# ESP32-P4 register map
Vendor: ESPRESSIF SYSTEMS (SHANGHAI) CO., LTD.; Series: ESP32 P-Series; File version: 3
CPU: RV32IMAFC r0p0, little endian, no MPU, FPU, 0 interrupt priority bits
Address unit: 32 bits
Registers are 32-bit, read-write, reset 0x0 unless marked. A register's access mark holds for its fields unless they carry their own. Offsets are from the block's base; [hi:lo] are bit positions; lines under a group give offsets from that group; {n}, {i} and the like mark numbered series; 'fields as' and 'values as' point back to an identical list.

## H264_DMA — H264 Encoder (DMA)
Base 0x500A7000
{0x0+0x100*i} OUT_CH{i} (i=0..4) group — Cluster OUT_CH{i}, containing OUT_CONF0_CH?, OUT_INT_RAW_CH?, OUT_INT_ENA_CH?, OUT_INT_ST_CH?, OUT_INT_CLR_CH?, OUTFIFO_STATUS_CH?, OUT_PUSH_CH?, OUT_LINK_CONF_CH?, OUT_LINK_ADDR_CH?, OUT_STATE_CH?, OUT_EOF_DES_ADDR_CH?, OUT_DSCR_CH?, OUT_DSCR_BF0_CH?, OUT_DSCR_BF1_CH?, OUT_ARB_CH?, OUT_RO_STATUS_CH?, OUT_RO_PD_CONF_CH?, OUT_MODE_ENABLE_CH?, OUT_MODE_YUV_CH?, OUT_ETM_CONF_CH?, OUT_BUF_LEN_CH?, OUT_FIFO_BCNT_CH?, OUT_PUSH_BYTECNT_CH?, OUT_XADDR_CH?, OUT_BLOCK_BUF_LEN_CH?
  0x00 CONF0 reset 0x2 — TX CHx config0 register
    [26] OUT_ARB_WEIGHT_OPT_DIS — Set this bit to 1 to disable arbiter optimum weight function.
    [25] OUT_CMD_DISABLE — Write 1 before reset and write 0 after reset
    [24] OUT_RST — Write 1 then write 0 to this bit to reset TX channel
    [16] OUT_REORDER_EN — Enable TX channel 0 macro block reorder when set to 1, only channel0 have this selection
    [12] OUT_PAGE_BOUND_EN — Set this bit to 1 to make sure AXI read data don't cross the address boundary which define by mem_burst_length
    [8:6] OUT_MEM_BURST_LENGTH — Block size of Tx channel 0. 0: single 1: 16 bytes 2: 32 bytes 3: 64 bytes 4: 128 bytes
    [4] OUT_CHECK_OWNER — Set this bit to enable checking the owner attribute of the link descriptor.
    [3] OUT_ECC_AES_EN — When access address space is ecc/aes area, this bit should be set to 1. In this case, the start address of square should be 16-bit aligned. The width of square multiply byte number of one pixel should be 16-bit aligned.
    [2] OUTDSCR_BURST_EN — Set this bit to 1 to enable INCR burst transfer for Tx channel 0 reading link descriptor when accessing internal SRAM.
    [1] OUT_EOF_MODE — EOF flag generation mode when receiving data. 1: EOF flag for Tx channel 0 is generated when data need to read has been popped from FIFO in DMA
    [0] OUT_AUTO_WRBACK — Set this bit to enable automatic outlink-writeback when all the data pointed by outlink descriptor has been received.
  0x04 INT_RAW — TX CHx interrupt raw register
    [8] OUT_DSCR_TASK_OVF — The raw interrupt bit turns to high level when dscr ready task fifo is overflow.
    [7] OUTFIFO_UDF_L2 — The raw interrupt bit turns to high level when fifo is underflow.
    [6] OUTFIFO_OVF_L2 — The raw interrupt bit turns to high level when fifo is overflow.
    [5] OUTFIFO_UDF_L1 — The raw interrupt bit turns to high level when fifo is underflow.
    [4] OUTFIFO_OVF_L1 — The raw interrupt bit turns to high level when fifo is overflow.
    [3] OUT_TOTAL_EOF — The raw interrupt bit turns to high level when data corresponding a outlink (includes one link descriptor or few link descriptors) is transmitted out for Tx channel 0.
    [2] OUT_DSCR_ERR — The raw interrupt bit turns to high level when detecting outlink descriptor error, including owner error, the second and third word error of outlink descriptor for Tx channel 0.
    [1] OUT_EOF — The raw interrupt bit turns to high level when the last data pointed by one outlink descriptor has been read from memory for Tx channel 0.
    [0] OUT_DONE — The raw interrupt bit turns to high level when the last data pointed by one outlink descriptor has been transmitted to peripherals for Tx channel 0.
  0x08 INT_ENA — TX CHx interrupt ena register
    [8] OUT_DSCR_TASK_OVF — The interrupt enable bit for the OUT_DSCR_TASK_OVF_CH_INT interrupt.
    [7] OUTFIFO_UDF_L2 — The interrupt enable bit for the OUTFIFO_UDF_L2_CH_INT interrupt.
    [6] OUTFIFO_OVF_L2 — The interrupt enable bit for the OUTFIFO_OVF_L2_CH_INT interrupt.
    [5] OUTFIFO_UDF_L1 — The interrupt enable bit for the OUTFIFO_UDF_L1_CH_INT interrupt.
    [4] OUTFIFO_OVF_L1 — The interrupt enable bit for the OUTFIFO_OVF_L1_CH_INT interrupt.
    [3] OUT_TOTAL_EOF — The interrupt enable bit for the OUT_TOTAL_EOF_CH_INT interrupt.
    [2] OUT_DSCR_ERR — The interrupt enable bit for the OUT_DSCR_ERR_CH_INT interrupt.
    [1] OUT_EOF — The interrupt enable bit for the OUT_EOF_CH_INT interrupt.
    [0] OUT_DONE — The interrupt enable bit for the OUT_DONE_CH_INT interrupt.
  0x0C INT_ST ro — TX CHx interrupt st register
    [8] OUT_DSCR_TASK_OVF — The raw interrupt status bit for the OUT_DSCR_TASK_OVF_CH_INT interrupt.
    [7] OUTFIFO_UDF_L2 — The raw interrupt status bit for the OUTFIFO_UDF_L2_CH_INT interrupt.
    [6] OUTFIFO_OVF_L2 — The raw interrupt status bit for the OUTFIFO_OVF_L2_CH_INT interrupt.
    [5] OUTFIFO_UDF_L1 — The raw interrupt status bit for the OUTFIFO_UDF_L1_CH_INT interrupt.
    [4] OUTFIFO_OVF_L1 — The raw interrupt status bit for the OUTFIFO_OVF_L1_CH_INT interrupt.
    [3] OUT_TOTAL_EOF — The raw interrupt status bit for the OUT_TOTAL_EOF_CH_INT interrupt.
    [2] OUT_DSCR_ERR — The raw interrupt status bit for the OUT_DSCR_ERR_CH_INT interrupt.
    [1] OUT_EOF — The raw interrupt status bit for the OUT_EOF_CH_INT interrupt.
    [0] OUT_DONE — The raw interrupt status bit for the OUT_DONE_CH_INT interrupt.
  0x10 INT_CLR wo — TX CHx interrupt clr register
    [8] OUT_DSCR_TASK_OVF write-1-clears — Set this bit to clear the OUT_DSCR_TASK_OVF_CH_INT interrupt.
    [7] OUTFIFO_UDF_L2 write-1-clears — Set this bit to clear the OUTFIFO_UDF_L2_CH_INT interrupt.
    [6] OUTFIFO_OVF_L2 write-1-clears — Set this bit to clear the OUTFIFO_OVF_L2_CH_INT interrupt.
    [5] OUTFIFO_UDF_L1 write-1-clears — Set this bit to clear the OUTFIFO_UDF_L1_CH_INT interrupt.
    [4] OUTFIFO_OVF_L1 write-1-clears — Set this bit to clear the OUTFIFO_OVF_L1_CH_INT interrupt.
    [3] OUT_TOTAL_EOF write-1-clears — Set this bit to clear the OUT_TOTAL_EOF_CH_INT interrupt.
    [2] OUT_DSCR_ERR write-1-clears — Set this bit to clear the OUT_DSCR_ERR_CH_INT interrupt.
    [1] OUT_EOF write-1-clears — Set this bit to clear the OUT_EOF_CH_INT interrupt.
    [0] OUT_DONE write-1-clears — Set this bit to clear the OUT_DONE_CH_INT interrupt.
  0x14 FIFO_STATUS ro reset 0x20082 — TX CHx outfifo status register
    [19:18] OUTFIFO_CNT_L3 — The register stores the 8byte number of the data in Tx FIFO for Tx channel 0.
    [17] OUTFIFO_EMPTY_L3 — Tx FIFO empty signal for Tx channel 0.
    [16] OUTFIFO_FULL_L3 — Tx FIFO full signal for Tx channel 0.
    [12:8] OUTFIFO_CNT_L1 — The register stores the byte number of the data in Tx FIFO for Tx channel 0.
    [7] OUTFIFO_EMPTY_L1 — Tx FIFO empty signal for Tx channel 0.
    [6] OUTFIFO_FULL_L1 — Tx FIFO full signal for Tx channel 0.
    [5:2] OUTFIFO_CNT_L2 — The register stores the byte number of the data in Tx FIFO for Tx channel 0.
    [1] OUTFIFO_EMPTY_L2 — Tx FIFO empty signal for Tx channel 0.
    [0] OUTFIFO_FULL_L2 — Tx FIFO full signal for Tx channel 0.
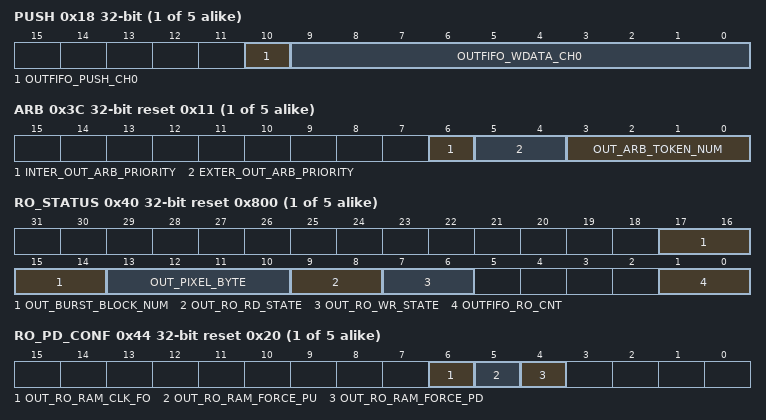
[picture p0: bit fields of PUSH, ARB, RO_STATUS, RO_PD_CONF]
  0x18 PUSH — TX CHx outfifo push register
    [10] OUTFIFO_PUSH_CH0 — Set this bit to push data into DMA Tx FIFO.
    [9:0] OUTFIFO_WDATA_CH0 — This register stores the data that need to be pushed into DMA Tx FIFO.
  0x1C LINK_CONF access per field reset 0x800000 — TX CHx out_link dscr ctrl register
    [23] OUTLINK_PARK ro — 1: the outlink descriptor's FSM is in idle state. 0: the outlink descriptor's FSM is working.
    [22] OUTLINK_RESTART rw — Set this bit to restart a new outlink from the last address.
    [21] OUTLINK_START rw — Set this bit to start dealing with the outlink descriptors.
    [20] OUTLINK_STOP rw — Set this bit to stop dealing with the outlink descriptors.
  0x20 LINK_ADDR — TX CHx out_link dscr addr register
    [31:0] OUTLINK_ADDR — This register stores the first outlink descriptor's address.
  0x24 STATE ro reset 0x1000000 — TX CHx state register
    [24] OUT_RESET_AVAIL — This register indicate that if the channel reset is safety.
    [23:20] OUT_STATE — This register stores the current control module state machine state.
    [19:18] OUT_DSCR_STATE — This register stores the current descriptor state machine state.
    [17:0] OUTLINK_DSCR_ADDR — This register stores the current outlink descriptor's address.
  0x28 EOF_DES_ADDR ro — TX CHx eof des addr register
    [31:0] OUT_EOF_DES_ADDR — This register stores the address of the outlink descriptor when the EOF bit in this descriptor is 1.
  0x2C DSCR ro — TX CHx next dscr addr register
    [31:0] OUTLINK_DSCR — The address of the next outlink descriptor address y.
  0x30 DSCR_BF0 ro — TX CHx last dscr addr register
    [31:0] OUTLINK_DSCR_BF0 — The address of the last outlink descriptor's next address y-1.
  0x34 DSCR_BF1 ro — TX CHx second-to-last dscr addr register
    [31:0] OUTLINK_DSCR_BF1 — The address of the second-to-last outlink descriptor's next address y-2.
  0x3C ARB reset 0x11 — TX CHx arb register
    [6] INTER_OUT_ARB_PRIORITY — Set the priority of channel
    [5:4] EXTER_OUT_ARB_PRIORITY — Set the priority of channel
    [3:0] OUT_ARB_TOKEN_NUM — Set the max number of token count of arbiter
  0x40 RO_STATUS ro reset 0x800 — TX CHx reorder status register. Available on CH0
    [17:14] OUT_BURST_BLOCK_NUM — the number of macro blocks contained in a burst of data at TX channel
    [13:10] OUT_PIXEL_BYTE — the number of bytes contained in a pixel at TX channel 0: 1byte 1: 1.5bytes 2 : 2bytes 3: 2.5bytes 4: 3bytes 5: 4bytes
    [9:8] OUT_RO_RD_STATE — The register stores the state of write ram of reorder
    [7:6] OUT_RO_WR_STATE — The register stores the state of read ram of reorder
    [1:0] OUTFIFO_RO_CNT — The register stores the 8byte number of the data in reorder Tx FIFO for channel 0.
  0x44 RO_PD_CONF reset 0x20 — TX CHx reorder power config register. Available on CH0
    [6] OUT_RO_RAM_CLK_FO — 1: Force to open the clock and bypass the gate-clock when accessing the RAM in DMA. 0: A gate-clock will be used when accessing the RAM in DMA.
    [5] OUT_RO_RAM_FORCE_PU — dma reorder ram power up
    [4] OUT_RO_RAM_FORCE_PD — dma reorder ram power down
  0x50 MODE_ENABLE — TX CHx mode enable register. Available on CH0
    [0] OUT_TEST_MODE_ENABLE — tx CH0 test mode enable.0 : H264_DMA work in normal mode.1 : H264_DMA work in test mode
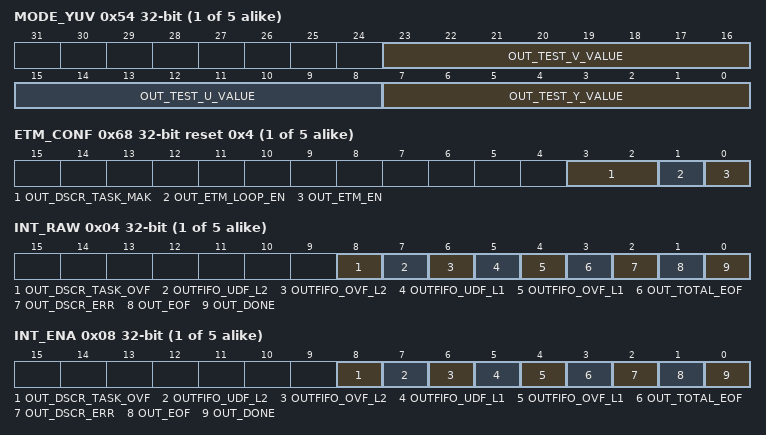
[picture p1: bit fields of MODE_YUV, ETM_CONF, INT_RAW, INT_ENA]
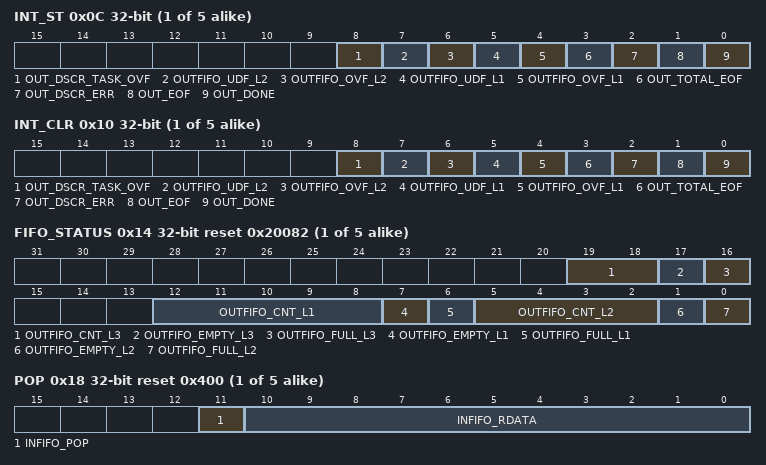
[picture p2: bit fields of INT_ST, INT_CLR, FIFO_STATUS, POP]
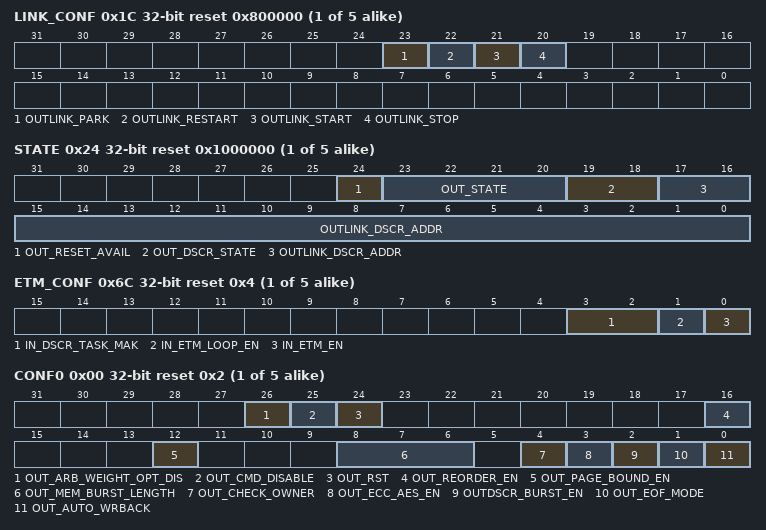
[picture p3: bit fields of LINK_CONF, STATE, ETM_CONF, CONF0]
  0x54 MODE_YUV — TX CHx test mode yuv value register. Available on CH0
    [23:16] OUT_TEST_V_VALUE — tx CH0 test mode v value
    [15:8] OUT_TEST_U_VALUE — tx CH0 test mode u value
    [7:0] OUT_TEST_Y_VALUE — tx CH0 test mode y value
  0x68 ETM_CONF reset 0x4 — TX CHx ETM config register
    [3:2] OUT_DSCR_TASK_MAK — ETM dscr_ready maximum cache numbers
    [1] OUT_ETM_LOOP_EN — when this bit is 1, dscr can be processed after receiving a task
    [0] OUT_ETM_EN — Set this bit to 1 to enable ETM task function
  0x70 BUF_LEN ro — TX CHx buf len register
    [27:0] OUT_CMDFIFO_BUF_LEN_HB — only for debug
  0x74 FIFO_BCNT ro — TX CHx fifo byte cnt register
    [9:0] OUT_CMDFIFO_OUTFIFO_BCNT — only for debug
  0x78 PUSH_BYTECNT ro reset 0xFF — TX CHx push byte cnt register
    [7:0] OUT_CMDFIFO_PUSH_BYTECNT — only for debug
  0x7C XADDR ro — TX CHx xaddr register
    [31:0] OUT_CMDFIFO_XADDR — only for debug
  0x80 BLOCK_BUF_LEN ro — TX CHx block buf len register
    [27:0] OUT_BLOCK_BUF_LEN — only for debug
{0x500+0x100*i} IN_CH{i} (i=0..4) group — Cluster IN_CH{i}, containing IN_CONF0_CH[0-4], IN_INT_RAW_CH[0-4], IN_INT_ENA_CH[0-4], IN_INT_ST_CH[0-4], IN_INT_CLR_CH[0-4], INFIFO_STATUS_CH[0-4], IN_POP_CH[0-4], IN_LINK_CONF_CH[0-4], IN_LINK_ADDR_CH[0-4], IN_STATE_CH[0-4], IN_SUC_EOF_DES_ADDR_CH[0-4], IN_ERR_EOF_DES_ADDR_CH[0-4], IN_DSCR_CH[0-4], IN_DSCR_BF0_CH[0-4], IN_DSCR_BF1_CH[0-4], IN_ARB_CH[0-4], IN_RO_PD_CONF_CH[0-4], IN_ETM_CONF_CH[0-4], IN_FIFO_CNT_CH[0-4], IN_POP_DATA_CNT_CH[0-4], IN_XADDR_CH[0-4], IN_BUF_HB_RCV_CH[0-4]
  0x00 CONF0 — RX CHx config0 register
    [26] IN_ARB_WEIGHT_OPT_DIS — Set this bit to 1 to disable arbiter optimum weight function.
    [25] IN_CMD_DISABLE — Write 1 before reset and write 0 after reset
    [24] IN_RST — Write 1 then write 0 to this bit to reset Rx channel
    [12] IN_PAGE_BOUND_EN — Set this bit to 1 to make sure AXI write data don't cross the address boundary which define by mem_burst_length
    [8:6] IN_MEM_BURST_LENGTH — Block size of Rx channel 0. 0: single 1: 16 bytes 2: 32 bytes 3: 64 bytes 4: 128 bytes
    [4] IN_CHECK_OWNER — Set this bit to enable checking the owner attribute of the link descriptor.
    [3] IN_ECC_AES_EN — When access address space is ecc/aes area, this bit should be set to 1. In this case, the start address of square should be 16-bit aligned. The width of square multiply byte number of one pixel should be 16-bit aligned.
    [2] INDSCR_BURST_EN — Set this bit to 1 to enable INCR burst transfer for Rx transmitting link descriptor when accessing SRAM.
  0x04 INT_RAW — RX CHx interrupt raw register
    [9] IN_DSCR_TASK_OVF — The raw interrupt bit turns to high level when dscr ready task fifo is overflow.
    [8] IN_DSCR_EMPTY — The raw interrupt bit turns to high level when the last descriptor is done but fifo also remain data.
    [7] INFIFO_UDF_L2 — The raw interrupt bit turns to high level when fifo of Rx channel is underflow.
    [6] INFIFO_OVF_L2 — The raw interrupt bit turns to high level when fifo of Rx channel is overflow.
    [5] INFIFO_UDF_L1 — The raw interrupt bit turns to high level when fifo of Rx channel is underflow.
    [4] INFIFO_OVF_L1 — The raw interrupt bit turns to high level when fifo of Rx channel is overflow.
    [3] IN_DSCR_ERR — The raw interrupt bit turns to high level when detecting inlink descriptor error, including owner error, the second and third word error of inlink descriptor for Rx channel 0.
    [2] IN_ERR_EOF — The raw interrupt bit turns to high level when the last data pointed by one inlink descriptor has been received and data error is detected
    [1] IN_SUC_EOF — The raw interrupt bit turns to high level when the last data pointed by one inlink descriptor has been received and no data error is detected for Rx channel 0.
    [0] IN_DONE — The raw interrupt bit turns to high level when the last data pointed by one inlink descriptor has been transmitted to peripherals for Rx channel 0.
  0x08 INT_ENA — RX CHx interrupt ena register
    [9] IN_DSCR_TASK_OVF — The interrupt enable bit for the IN_DSCR_TASK_OVF_CH_INT interrupt.
    [8] IN_DSCR_EMPTY — The interrupt enable bit for the IN_DSCR_EMPTY_CH_INT interrupt.
    [7] INFIFO_UDF_L2 — The interrupt enable bit for the INFIFO_UDF_L2_CH_INT interrupt.
    [6] INFIFO_OVF_L2 — The interrupt enable bit for the INFIFO_OVF_L2_CH_INT interrupt.
    [5] INFIFO_UDF_L1 — The interrupt enable bit for the INFIFO_UDF_L1_CH_INT interrupt.
    [4] INFIFO_OVF_L1 — The interrupt enable bit for the INFIFO_OVF_L1_CH_INT interrupt.
    [3] IN_DSCR_ERR — The interrupt enable bit for the IN_DSCR_ERR_CH_INT interrupt.
    [2] IN_ERR_EOF — The interrupt enable bit for the IN_ERR_EOF_CH_INT interrupt.
    [1] IN_SUC_EOF — The interrupt enable bit for the IN_SUC_EOF_CH_INT interrupt.
    [0] IN_DONE — The interrupt enable bit for the IN_DONE_CH_INT interrupt.
  0x0C INT_ST ro — RX CHx interrupt st register
    [9] IN_DSCR_TASK_OVF — The raw interrupt status bit for the IN_DSCR_TASK_OVF_CH_INT interrupt.
    [8] IN_DSCR_EMPTY — The raw interrupt status bit for the IN_DSCR_EMPTY_CH_INT interrupt.
    [7] INFIFO_UDF_L2 — The raw interrupt status bit for the INFIFO_UDF_L2_CH_INT interrupt.
    [6] INFIFO_OVF_L2 — The raw interrupt status bit for the INFIFO_OVF_L2_CH_INT interrupt.
    [5] INFIFO_UDF_L1 — The raw interrupt status bit for the INFIFO_UDF_L1_CH_INT interrupt.
    [4] INFIFO_OVF_L1 — The raw interrupt status bit for the INFIFO_OVF_L1_CH_INT interrupt.
    [3] IN_DSCR_ERR — The raw interrupt status bit for the IN_DSCR_ERR_CH_INT interrupt.
    [2] IN_ERR_EOF — The raw interrupt status bit for the IN_ERR_EOF_CH_INT interrupt.
    [1] IN_SUC_EOF — The raw interrupt status bit for the IN_SUC_EOF_CH_INT interrupt.
    [0] IN_DONE — The raw interrupt status bit for the IN_DONE_CH_INT interrupt.
  0x10 INT_CLR wo — RX CHx interrupt clr register
    [9] IN_DSCR_TASK_OVF write-1-clears — Set this bit to clear the IN_DSCR_TASK_OVF_CH_INT interrupt.
    [8] IN_DSCR_EMPTY write-1-clears — Set this bit to clear the IN_DSCR_EMPTY_CH_INT interrupt.
    [7] INFIFO_UDF_L2 write-1-clears — Set this bit to clear the INFIFO_UDF_L2_CH_INT interrupt.
    [6] INFIFO_OVF_L2 write-1-clears — Set this bit to clear the INFIFO_OVF_L2_CH_INT interrupt.
    [5] INFIFO_UDF_L1 write-1-clears — Set this bit to clear the INFIFO_UDF_L1_CH_INT interrupt.
    [4] INFIFO_OVF_L1 write-1-clears — Set this bit to clear the INFIFO_OVF_L1_CH_INT interrupt.
    [3] IN_DSCR_ERR write-1-clears — Set this bit to clear the INDSCR_ERR_CH_INT interrupt.
    [2] IN_ERR_EOF write-1-clears — Set this bit to clear the IN_ERR_EOF_CH_INT interrupt.
    [1] IN_SUC_EOF write-1-clears — Set this bit to clear the IN_SUC_EOF_CH_INT interrupt.
    [0] IN_DONE write-1-clears — Set this bit to clear the IN_DONE_CH_INT interrupt.
  0x14 FIFO_STATUS ro reset 0x20082 — RX CHx INFIFO status register
    [19:18] INFIFO_CNT_L3 — The register stores the 8byte number of the data in Tx FIFO for Tx channel 0.
    [17] INFIFO_EMPTY_L3 — Tx FIFO empty signal for Tx channel 0.
    [16] INFIFO_FULL_L3 — Tx FIFO full signal for Tx channel 0.
    [12:8] INFIFO_CNT_L1 — The register stores the byte number of the data in Tx FIFO for Tx channel 0.
    [7] INFIFO_EMPTY_L1 — Tx FIFO empty signal for Tx channel 0.
    [6] INFIFO_FULL_L1 — Tx FIFO full signal for Tx channel 0.
    [5:2] INFIFO_CNT_L2 — The register stores the byte number of the data in Rx FIFO for Rx channel.
    [1] INFIFO_EMPTY_L2 — Rx FIFO empty signal for Rx channel.
    [0] INFIFO_FULL_L2 — Rx FIFO full signal for Rx channel.
  0x18 POP access per field reset 0x400 — RX CHx INFIFO pop register
    [11] INFIFO_POP rw — Set this bit to pop data from DMA Rx FIFO.
    [10:0] INFIFO_RDATA ro — This register stores the data popping from DMA Rx FIFO.
  0x1C LINK_CONF access per field reset 0x1100000 — RX CHx in_link dscr ctrl register
    [24] INLINK_PARK ro — 1: the inlink descriptor's FSM is in idle state. 0: the inlink descriptor's FSM is working.
    [23] INLINK_RESTART rw — Set this bit to mount a new inlink descriptor.
    [22] INLINK_START rw — Set this bit to start dealing with the inlink descriptors.
    [21] INLINK_STOP rw — Set this bit to stop dealing with the inlink descriptors.
    [20] INLINK_AUTO_RET rw — Set this bit to return to current inlink descriptor's address, when there are some errors in current receiving data.
  0x20 LINK_ADDR — RX CHx in_link dscr addr register
    [31:0] INLINK_ADDR — This register stores the first inlink descriptor's address.
  0x24 STATE ro reset 0x800000 — RX CHx state register
    [23] IN_RESET_AVAIL — This register indicate that if the channel reset is safety.
    [22:20] IN_STATE — This register stores the current control module state machine state.
    [19:18] IN_DSCR_STATE — This register stores the current descriptor state machine state.
    [17:0] INLINK_DSCR_ADDR — This register stores the current inlink descriptor's address.
  0x28 SUC_EOF_DES_ADDR ro — RX CHx eof des addr register
    [31:0] IN_SUC_EOF_DES_ADDR — This register stores the address of the inlink descriptor when the EOF bit in this descriptor is 1.
  0x2C ERR_EOF_DES_ADDR ro — RX CHx err eof des addr register
    [31:0] IN_ERR_EOF_DES_ADDR — This register stores the address of the inlink descriptor when there are some errors in current receiving data.
  0x30 DSCR ro — RX CHx next dscr addr register
    [31:0] INLINK_DSCR — The address of the next inlink descriptor address x.
  0x34 DSCR_BF0 ro — RX CHx last dscr addr register
    [31:0] INLINK_DSCR_BF0 — The address of the last inlink descriptor's next address x-1.
  0x38 DSCR_BF1 ro — RX CHx second-to-last dscr addr register
    [31:0] INLINK_DSCR_BF1 — The address of the second-to-last inlink descriptor's next address x-2.
  0x40 ARB reset 0x51 — RX CHx arb register
    [8:6] INTER_IN_ARB_PRIORITY — Set the priority of channel
    [5:4] EXTER_IN_ARB_PRIORITY — Set the priority of channel
    [3:0] IN_ARB_TOKEN_NUM — Set the max number of token count of arbiter
  0x48 RO_PD_CONF — RX CHx reorder power config register. Available on CH0
    [6] IN_RO_RAM_CLK_FO — 1: Force to open the clock and bypass the gate-clock when accessing the RAM in DMA. 0: A gate-clock will be used when accessing the RAM in DMA.
  0x6C ETM_CONF reset 0x4 — RX CHx ETM config register
    [3:2] IN_DSCR_TASK_MAK — ETM dscr_ready maximum cache numbers
    [1] IN_ETM_LOOP_EN — when this bit is 1, dscr can be processed after receiving a task
    [0] IN_ETM_EN — Set this bit to 1 to enable ETM task function
  0x80 FIFO_CNT ro — RX CHx fifo cnt register
    [9:0] IN_CMDFIFO_INFIFO_CNT — only for debug
  0x84 POP_DATA_CNT ro reset 0x7 — RX CHx pop data cnt register
    [7:0] IN_CMDFIFO_POP_DATA_CNT — only for debug
  0x88 XADDR ro — RX CHx xaddr register
    [31:0] IN_CMDFIFO_XADDR — only for debug
  0x8C BUF_HB_RCV ro — RX CH0 buf len hb rcv register
    [28:0] IN_CMDFIFO_BUF_HB_RCV — only for debug
0xA00 IN_CH5 group — Cluster IN_CH5, containing IN_CONF0_CH5, IN_CONF1_CH5, IN_CONF2_CH5, IN_CONF3_CH5, IN_INT_RAW_CH5, IN_INT_ENA_CH5, IN_INT_ST_CH5, IN_INT_CLR_CH5, INFIFO_STATUS_CH5, IN_POP_CH5, IN_STATE_CH5, IN_ARB_CH5, IN_FIFO_CNT_CH5, IN_POP_DATA_CNT_CH5, IN_XADDR_CH5, IN_BUF_HB_RCV_CH5
  0x00 CONF0 — RX CH5 config0 register
    [25] IN_CMD_DISABLE — Write 1 before reset and write 0 after reset
    [24] IN_RST — Write 1 then write 0 to this bit to reset Rx channel
    [12] IN_PAGE_BOUND_EN — Set this bit to 1 to make sure AXI write data don't cross the address boundary which define by mem_burst_length
    [8:6] IN_MEM_BURST_LENGTH — Block size of Rx channel 1. 0: single 1: 16 bytes 2: 32 bytes 3: 64 bytes 4: 128 bytes
    [3] IN_ECC_AES_EN — When access address space is ecc/aes area, this bit should be set to 1. In this case, the start address of square should be 16-bit aligned. The width of square multiply byte number of one pixel should be 16-bit aligned.
  0x04 CONF1 — RX CH5 config1 register
    [31:0] BLOCK_START_ADDR — RX Channel 5 destination start address
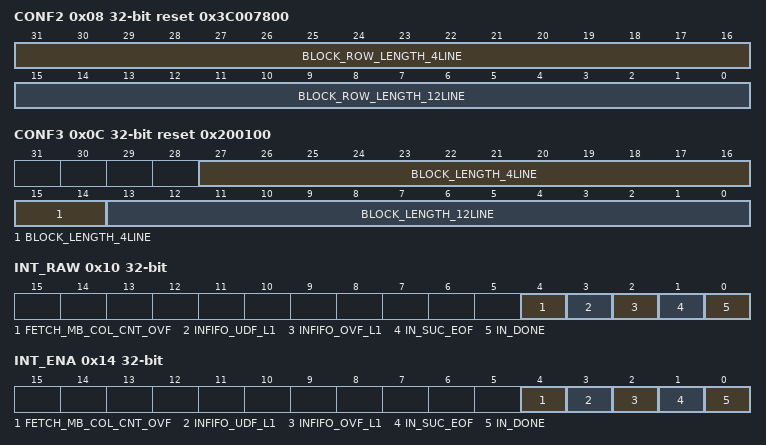
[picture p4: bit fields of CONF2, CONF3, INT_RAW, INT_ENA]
  0x08 CONF2 reset 0x3C007800 — RX CH5 config2 register
    [31:16] BLOCK_ROW_LENGTH_4LINE — The number of bytes contained in a row block 4line in RX channel 5
    [15:0] BLOCK_ROW_LENGTH_12LINE — The number of bytes contained in a row block 12line in RX channel 5
  0x0C CONF3 reset 0x200100 — RX CH5 config3 register
    [27:14] BLOCK_LENGTH_4LINE — The number of bytes contained in a block 4line
    [13:0] BLOCK_LENGTH_12LINE — The number of bytes contained in a block 12line
  0x10 INT_RAW — RX CH5 interrupt raw register
    [4] FETCH_MB_COL_CNT_OVF — This raw interrupt bit turns to high level when fifo of Rx channel is underflow.
    [3] INFIFO_UDF_L1 — This raw interrupt bit turns to high level when fifo of Rx channel is underflow.
    [2] INFIFO_OVF_L1 — This raw interrupt bit turns to high level when fifo of Rx channel is overflow.
    [1] IN_SUC_EOF — The raw interrupt bit turns to high level when the last data pointed by one inlink descriptor has been received and no data error is detected for Rx channel 1.
    [0] IN_DONE — The raw interrupt bit turns to high level when the last data pointed by one inlink descriptor has been transmitted to peripherals for Rx channel 1.
  0x14 INT_ENA — RX CH5 interrupt ena register
    [4] FETCH_MB_COL_CNT_OVF — The interrupt enable bit for the INFIFO_UDF_L1_CH_INT interrupt.
    [3] INFIFO_UDF_L1 — The interrupt enable bit for the INFIFO_UDF_L1_CH_INT interrupt.
    [2] INFIFO_OVF_L1 — The interrupt enable bit for the INFIFO_OVF_L1_CH_INT interrupt.
    [1] IN_SUC_EOF — The interrupt enable bit for the IN_SUC_EOF_CH_INT interrupt.
    [0] IN_DONE — The interrupt enable bit for the IN_DONE_CH_INT interrupt.
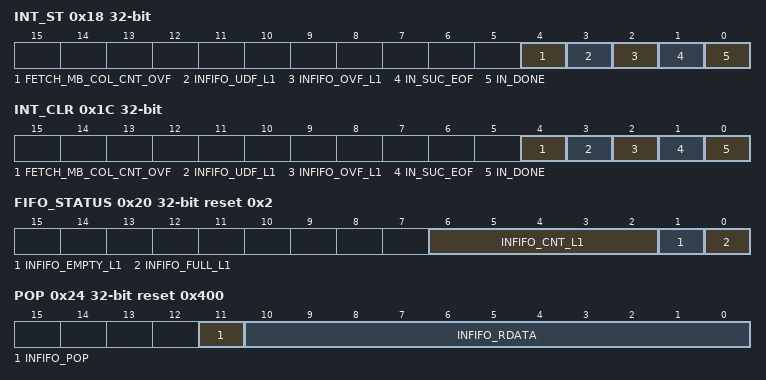
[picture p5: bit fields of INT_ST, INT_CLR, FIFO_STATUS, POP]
  0x18 INT_ST ro — RX CH5 interrupt st register
    [4] FETCH_MB_COL_CNT_OVF — The raw interrupt status bit for the INFIFO_UDF_L1_CH_INT interrupt.
    [3] INFIFO_UDF_L1 — The raw interrupt status bit for the INFIFO_UDF_L1_CH_INT interrupt.
    [2] INFIFO_OVF_L1 — The raw interrupt status bit for the INFIFO_OVF_L1_CH_INT interrupt.
    [1] IN_SUC_EOF — The raw interrupt status bit for the IN_SUC_EOF_CH_INT interrupt.
    [0] IN_DONE — The raw interrupt status bit for the IN_DONE_CH_INT interrupt.
  0x1C INT_CLR wo — RX CH5 interrupt clr register
    [4] FETCH_MB_COL_CNT_OVF write-1-clears — Set this bit to clear the INFIFO_UDF_L1_CH_INT interrupt.
    [3] INFIFO_UDF_L1 write-1-clears — Set this bit to clear the INFIFO_UDF_L1_CH_INT interrupt.
    [2] INFIFO_OVF_L1 write-1-clears — Set this bit to clear the INFIFO_OVF_L1_CH_INT interrupt.
    [1] IN_SUC_EOF write-1-clears — Set this bit to clear the IN_SUC_EOF_CH_INT interrupt.
    [0] IN_DONE write-1-clears — Set this bit to clear the IN_DONE_CH_INT interrupt.
  0x20 FIFO_STATUS ro reset 0x2 — RX CH5 INFIFO status register
    [6:2] INFIFO_CNT_L1 — The register stores the byte number of the data in Tx FIFO for Tx channel 1.
    [1] INFIFO_EMPTY_L1 — Tx FIFO empty signal for Tx channel 1.
    [0] INFIFO_FULL_L1 — Tx FIFO full signal for Tx channel 1.
  0x24 POP access per field reset 0x400 — RX CH5 INFIFO pop register
    fields as IN_CH0.POP
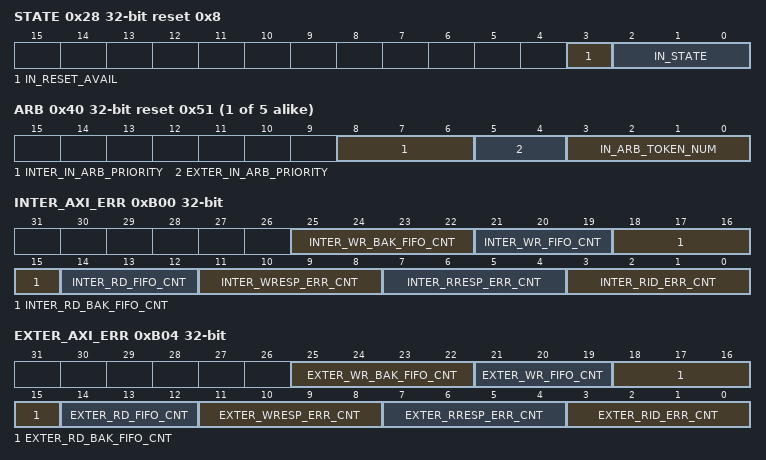
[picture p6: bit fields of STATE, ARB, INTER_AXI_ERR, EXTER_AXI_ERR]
  0x28 STATE ro reset 0x8 — RX CH5 state register
    [3] IN_RESET_AVAIL — This register indicate that if the channel reset is safety.
    [2:0] IN_STATE — This register stores the current control module state machine state.
  0x40 ARB reset 0x41 — RX CH5 arb register
    [8:6] INTER_IN_ARB_PRIORITY — Set the priority of channel
    [3:0] IN_ARB_TOKEN_NUM — Set the max number of token count of arbiter
  0x80 FIFO_CNT ro — rx CH5 fifo cnt register
    [9:0] IN_CMDFIFO_INFIFO_CNT — only for debug
  0x84 POP_DATA_CNT ro reset 0xFF — rx CH5 pop data cnt register
    [7:0] IN_CMDFIFO_POP_DATA_CNT — only for debug
  0x88 XADDR ro — rx CH5 xaddr register
    [31:0] IN_CMDFIFO_XADDR — only for debug
  0x8C BUF_HB_RCV ro — rx CH5 buf len hb rcv register
    [28:0] IN_CMDFIFO_BUF_HB_RCV — only for debug
0xB00 INTER_AXI_ERR ro — inter memory axi err register
  [25:22] INTER_WR_BAK_FIFO_CNT — AXI write backup cmd fifo remain cmd count
  [21:19] INTER_WR_FIFO_CNT — AXI write cmd fifo remain cmd count
  [18:15] INTER_RD_BAK_FIFO_CNT — AXI read backup cmd fifo remain cmd count
  [14:12] INTER_RD_FIFO_CNT — AXI read cmd fifo remain cmd count
  [11:8] INTER_WRESP_ERR_CNT — AXI write resp err cnt
  [7:4] INTER_RRESP_ERR_CNT — AXI read resp err cnt
  [3:0] INTER_RID_ERR_CNT — AXI read id err cnt
0xB04 EXTER_AXI_ERR ro — exter memory axi err register
  [25:22] EXTER_WR_BAK_FIFO_CNT — AXI write backup cmd fifo remain cmd count
  [21:19] EXTER_WR_FIFO_CNT — AXI write cmd fifo remain cmd count
  [18:15] EXTER_RD_BAK_FIFO_CNT — AXI read backup cmd fifo remain cmd count
  [14:12] EXTER_RD_FIFO_CNT — AXI read cmd fifo remain cmd count
  [11:8] EXTER_WRESP_ERR_CNT — AXI write resp err cnt
  [7:4] EXTER_RRESP_ERR_CNT — AXI read resp err cnt
  [3:0] EXTER_RID_ERR_CNT — AXI read id err cnt
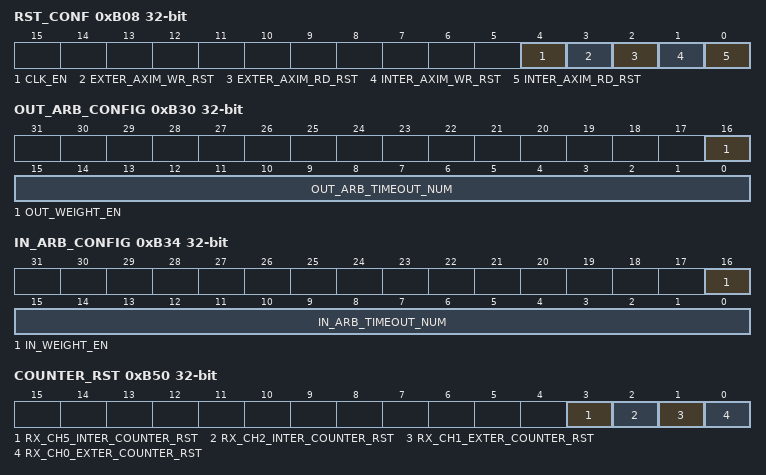
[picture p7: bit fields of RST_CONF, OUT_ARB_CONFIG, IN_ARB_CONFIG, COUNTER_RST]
0xB08 RST_CONF — axi reset config register
  [4] CLK_EN — 1'h1: Force clock on for register. 1'h0: Support clock only when application writes registers.
  [3] EXTER_AXIM_WR_RST — Write 1 then write 0 to this bit to reset axi master write data FIFO.
  [2] EXTER_AXIM_RD_RST — Write 1 then write 0 to this bit to reset axi master read data FIFO.
  [1] INTER_AXIM_WR_RST — Write 1 then write 0 to this bit to reset axi master write data FIFO.
  [0] INTER_AXIM_RD_RST — Write 1 then write 0 to this bit to reset axi master read data FIFO.
0xB0C INTER_MEM_START_ADDR0 reset 0x30100000 — Start address of inter memory range0 register
  [31:0] ACCESS_INTER_MEM_START_ADDR0 — The start address of accessible address space.
0xB10 INTER_MEM_END_ADDR0 reset 0x8FFFFFFF — end address of inter memory range0 register
  [31:0] ACCESS_INTER_MEM_END_ADDR0 — The end address of accessible address space. The access address beyond this range would lead to descriptor error.
0xB14 INTER_MEM_START_ADDR1 reset 0x30100000 — Start address of inter memory range1 register
  [31:0] ACCESS_INTER_MEM_START_ADDR1 — The start address of accessible address space.
0xB18 INTER_MEM_END_ADDR1 reset 0x8FFFFFFF — end address of inter memory range1 register
  [31:0] ACCESS_INTER_MEM_END_ADDR1 — The end address of accessible address space. The access address beyond this range would lead to descriptor error.
0xB20 EXTER_MEM_START_ADDR0 reset 0x30100000 — Start address of exter memory range0 register
  [31:0] ACCESS_EXTER_MEM_START_ADDR0 — The start address of accessible address space.
0xB24 EXTER_MEM_END_ADDR0 reset 0x8FFFFFFF — end address of exter memory range0 register
  [31:0] ACCESS_EXTER_MEM_END_ADDR0 — The end address of accessible address space. The access address beyond this range would lead to descriptor error.
0xB28 EXTER_MEM_START_ADDR1 reset 0x30100000 — Start address of exter memory range1 register
  [31:0] ACCESS_EXTER_MEM_START_ADDR1 — The start address of accessible address space.
0xB2C EXTER_MEM_END_ADDR1 reset 0x8FFFFFFF — end address of exter memory range1 register
  [31:0] ACCESS_EXTER_MEM_END_ADDR1 — The end address of accessible address space. The access address beyond this range would lead to descriptor error.
0xB30 OUT_ARB_CONFIG — reserved
  [16] OUT_WEIGHT_EN — reserved
  [15:0] OUT_ARB_TIMEOUT_NUM — Set the max number of timeout count of arbiter
0xB34 IN_ARB_CONFIG — reserved
  [16] IN_WEIGHT_EN — reserved
  [15:0] IN_ARB_TIMEOUT_NUM — Set the max number of timeout count of arbiter
0xB3C DATE reset 0x20230403 — reserved
  [31:0] DATE — register version.
0xB50 COUNTER_RST — counter reset register
  [3] RX_CH5_INTER_COUNTER_RST — Write 1 then write 0 to this bit to reset rx ch5 counter.
  [2] RX_CH2_INTER_COUNTER_RST — Write 1 then write 0 to this bit to reset rx ch2 counter.
  [1] RX_CH1_EXTER_COUNTER_RST — Write 1 then write 0 to this bit to reset rx ch1 counter.
  [0] RX_CH0_EXTER_COUNTER_RST — Write 1 then write 0 to this bit to reset rx ch0 counter.
0xB54 RX_CH0_COUNTER ro
  [22:0] RX_CH0_CNT
0xB58 RX_CH1_COUNTER ro
  [20:0] RX_CH1_CNT
0xB5C RX_CH2_COUNTER ro
  [10:0] RX_CH2_CNT
0xB60 RX_CH5_COUNTER ro
  [16:0] RX_CH5_CNT
0xB64 PBYTE reset 0x2 — image pbyte register
  [3:0] ORI_PBYTE — configures bytes per pixel for ori img. 0: 0.5byte/pix, 1: 1byte/pix, 2: 1.5byte/pix, 3: 2byte/pix, 4: 3byte/pix
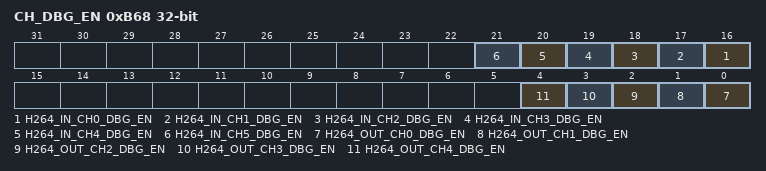
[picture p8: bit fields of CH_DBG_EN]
0xB68 CH_DBG_EN — channel debug enable register
  [n+16] H264_IN_CH{n}_DBG_EN (n=0..5) — configures whether to enable in channel {n} debug. 0: disable, 1: enable
  [n] H264_OUT_CH{n}_DBG_EN (n=0..4) — configures whether to enable out channel {n} debug. 0: disable, 1: enable
{0xB6C+8i} OUT_CH{i}_DBG_DATA_L (i=0..4) — out channel {i} debug data register
  [31:0] H264_OUT_CH{i}_DBG_DATA_L — configures out channel {i} debug data bit 31-0
{0xB70+8i} OUT_CH{i}_DBG_DATA_H (i=0..4) — out channel {i} debug data register
  [31:0] H264_OUT_CH{i}_DBG_DATA_H — configures out channel {i} debug data bit 63-32
{0xB94+8i} IN_CH{i}_DBG_DATA_L (i=0..5) — in channel {i} debug data register
  [31:0] H264_IN_CH{i}_DBG_DATA_L — configures in channel {i} debug data bit 31-0
{0xB98+8i} IN_CH{i}_DBG_DATA_H (i=0..5) — in channel {i} debug data register
  [31:0] H264_IN_CH{i}_DBG_DATA_H — configures in channel {i} debug data bit 63-32
